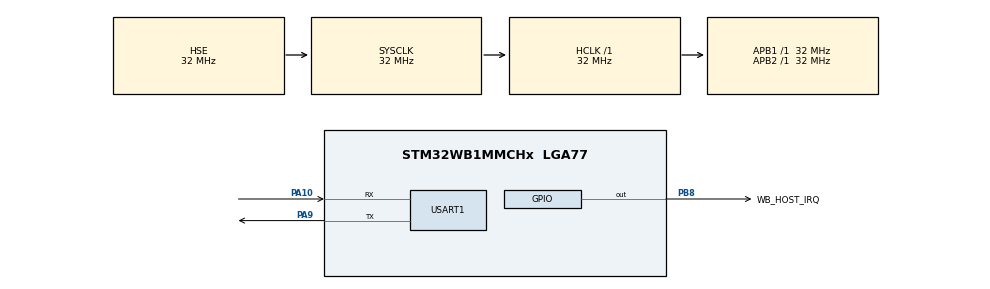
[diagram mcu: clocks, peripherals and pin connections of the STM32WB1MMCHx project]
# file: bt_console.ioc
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CRC.CRCLength=CRC_POLYLENGTH_16B
CRC.DefaultInitValueUse=DEFAULT_INIT_VALUE_DISABLE
CRC.DefaultPolynomialUse=DEFAULT_POLYNOMIAL_DISABLE
CRC.GeneratingPolynomial=X12+X5+X0
CRC.InitValue=0xFFFF
IWDG.Prescaler=IWDG_PRESCALER_128
IWDG.Reload=1999
Mcu.Family=STM32WB
Mcu.Name=STM32WB1MMCHx
Mcu.Package=LGA77
NVIC.HSEM_IRQn=true\:0\:0\:false\:false\:true\:false\:true\:true
NVIC.IPCC_C1_RX_IRQn=true\:0\:0\:false\:false\:true\:true\:true\:true
NVIC.IPCC_C1_TX_IRQn=true\:0\:0\:false\:false\:true\:true\:true\:true
NVIC.LPTIM1_IRQn=true\:6\:0\:true\:false\:true\:true\:true\:true
NVIC.PriorityGroup=NVIC_PRIORITYGROUP_4
NVIC.RTC_WKUP_IRQn=true\:3\:0\:true\:false\:true\:true\:true\:true
NVIC.USART1_IRQn=true\:5\:0\:true\:false\:true\:true\:true\:true
PA10.Mode=Asynchronous
PA10.Signal=USART1_RX
PA13.Mode=Serial_Wire
PA13.Signal=SYS_JTMS-SWDIO
PA14.Mode=Serial_Wire
PA14.Signal=SYS_JTCK-SWCLK
PA9.Mode=Asynchronous
PA9.Signal=USART1_TX
PB8.GPIO_Label=WB_HOST_IRQ
PB8.Signal=GPIO_Output
ProjectManager.HeapSize=0x200
ProjectManager.StackSize=0x400
ProjectManager.TargetToolchain=STM32CubeIDE
RCC.AHBFreq_Value=32000000
RCC.APB1Freq_Value=32000000
RCC.APB1TimFreq_Value=32000000
RCC.APB2Freq_Value=32000000
RCC.APB2TimFreq_Value=32000000
RCC.APB3Freq_Value=16000000
RCC.CortexFreq_Value=32000000
RCC.HCLKFreq_Value=32000000
RCC.HSE_VALUE=32000000
RCC.HSI_VALUE=16000000
RCC.LPTIM1CLockSelection=RCC_LPTIM1CLKSOURCE_LSE
RCC.RFWKPClockSelection=RCC_RFWKPCLKSOURCE_LSE
RCC.RTCClockSelection=RCC_RTCCLKSOURCE_LSE
RCC.SMPSCLockSelectionVirtual=RCC_SMPSCLKSOURCE_HSE
RCC.SMPSDivider=4
RCC.SYSCLKFreq_VALUE=32000000
RCC.SYSCLKSource=RCC_SYSCLKSOURCE_HSE
RCC.VCOOutputFreq_Value=32000000
STM32_WPAN.BLE_APPLICATION_TYPE=BLE_CLIENT_PROFILE
STM32_WPAN.BLE_CFG_CLT_MAX_NBR_CB=2
STM32_WPAN.CFG_LSCLK_LSE=0
USART1.VirtualMode-Asynchronous=VM_ASYNC
VP_CRC_VS_CRC.Mode=CRC_Activate
VP_HSEM_VS_HSEM.Mode=HSEM_Activate
VP_IPCC_VS_IPCC.Mode=IPCC_Activate
VP_IWDG_VS_IWDG.Mode=IWDG_Activate
VP_LPTIM1_VS_LPTIM_counterModeInternalClock.Mode=Counts__internal_clock_event_00
VP_MEMORYMAP_VS_MEMORYMAP.Mode=CurAppReg
VP_RCC_V_OSC32_IN.Mode=LSE-External-Clock-Source
VP_RCC_V_OSC_IN.Mode=HSE-External-Clock-Source
VP_RF_VS_RF.Mode=RF_Activate
VP_RTC_VS_RTC_Activate.Mode=RTC_Enabled
VP_RTC_VS_RTC_WakeUp_intern.Mode=WakeUp
VP_SEQUENCER_VS_SEQUENCER.Mode=SEQUENCER_Enabled
VP_STM32_WPAN_VS_BLE_HOST.Mode=STM32_WPAN_Enabled
VP_TINY_LPM_VS_TINY_LPM.Mode=TINY_LPM_Enabled
board=custom

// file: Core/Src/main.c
/* USER CODE BEGIN Header */
/**
  ******************************************************************************
  * @file           : main.c
  * @brief          : Main program body
  ******************************************************************************
  * @attention
  *
  * Copyright (c) 2026 STMicroelectronics.
  * All rights reserved.
  *
  * This software is licensed under terms that can be found in the LICENSE file
  * in the root directory of this software component.
  * If no LICENSE file comes with this software, it is provided AS-IS.
  *
  ******************************************************************************
  */
/* USER CODE END Header */
#include "main.h"

/* USER CODE BEGIN Includes */

#include "error.h"
#include "watchdog.h"

/* USER CODE END Includes */

CRC_HandleTypeDef hcrc;

IPCC_HandleTypeDef hipcc;

IWDG_HandleTypeDef hiwdg;

LPTIM_HandleTypeDef hlptim1;

RTC_HandleTypeDef hrtc;

UART_HandleTypeDef huart1;

void SystemClock_Config(void);
void PeriphCommonClock_Config(void);
static void MX_GPIO_Init(void);
static void MX_IPCC_Init(void);
static void MX_RTC_Init(void);
static void MX_USART1_UART_Init(void);
static void MX_CRC_Init(void);
static void MX_LPTIM1_Init(void);
static void MX_IWDG_Init(void);
static void MX_RF_Init(void);

int main(void)
{

  /* MCU Configuration--------------------------------------------------------*/

  /* Reset of all peripherals, Initializes the Flash interface and the Systick. */
  HAL_Init();
  /* Config code for STM32_WPAN (HSE Tuning must be done before system clock configuration) */
  MX_APPE_Config();

  /* Configure the system clock */
  SystemClock_Config();

  /* Configure the peripherals common clocks */
  PeriphCommonClock_Config();

  /* IPCC initialisation */
  MX_IPCC_Init();

  /* Initialize all configured peripherals */
  MX_GPIO_Init();
  MX_RTC_Init();
  MX_USART1_UART_Init();
  MX_CRC_Init();
  MX_LPTIM1_Init();
  MX_IWDG_Init();
  MX_RF_Init();

  /* Init code for STM32_WPAN */
  MX_APPE_Init();

  /* Infinite loop */
  while (1)
  {
    MX_APPE_Process();

    /* USER CODE BEGIN 3 */
    watchdog_process();
  }
  /* USER CODE END 3 */
}

void SystemClock_Config(void)
{
  RCC_OscInitTypeDef RCC_OscInitStruct = {0};
  RCC_ClkInitTypeDef RCC_ClkInitStruct = {0};

  /** Configure LSE Drive Capability
  */
  HAL_PWR_EnableBkUpAccess();
  __HAL_RCC_LSEDRIVE_CONFIG(RCC_LSEDRIVE_MEDIUMHIGH);

  /** Initializes the RCC Oscillators according to the specified parameters
  * in the RCC_OscInitTypeDef structure.
  */
  RCC_OscInitStruct.OscillatorType = RCC_OSCILLATORTYPE_HSI|RCC_OSCILLATORTYPE_LSI1
                              |RCC_OSCILLATORTYPE_HSE|RCC_OSCILLATORTYPE_LSE;
  RCC_OscInitStruct.HSEState = RCC_HSE_ON;
  RCC_OscInitStruct.LSEState = RCC_LSE_ON;
  RCC_OscInitStruct.HSIState = RCC_HSI_ON;
  RCC_OscInitStruct.HSICalibrationValue = RCC_HSICALIBRATION_DEFAULT;
  RCC_OscInitStruct.LSIState = RCC_LSI_ON;
  RCC_OscInitStruct.PLL.PLLState = RCC_PLL_NONE;
  if (HAL_RCC_OscConfig(&RCC_OscInitStruct) != HAL_OK)
  {
    Error_Handler();
  }

  /** Configure the SYSCLKSource, HCLK, PCLK1 and PCLK2 clocks dividers
  */
  RCC_ClkInitStruct.ClockType = RCC_CLOCKTYPE_HCLK4|RCC_CLOCKTYPE_HCLK2
                              |RCC_CLOCKTYPE_HCLK|RCC_CLOCKTYPE_SYSCLK
                              |RCC_CLOCKTYPE_PCLK1|RCC_CLOCKTYPE_PCLK2;
  RCC_ClkInitStruct.SYSCLKSource = RCC_SYSCLKSOURCE_HSE;
  RCC_ClkInitStruct.AHBCLKDivider = RCC_SYSCLK_DIV1;
  RCC_ClkInitStruct.APB1CLKDivider = RCC_HCLK_DIV1;
  RCC_ClkInitStruct.APB2CLKDivider = RCC_HCLK_DIV1;
  RCC_ClkInitStruct.AHBCLK2Divider = RCC_SYSCLK_DIV1;
  RCC_ClkInitStruct.AHBCLK4Divider = RCC_SYSCLK_DIV1;

  if (HAL_RCC_ClockConfig(&RCC_ClkInitStruct, FLASH_LATENCY_1) != HAL_OK)
  {
    Error_Handler();
  }
}

void PeriphCommonClock_Config(void)
{
  RCC_PeriphCLKInitTypeDef PeriphClkInitStruct = {0};

  /** Initializes the peripherals clock
  */
  PeriphClkInitStruct.PeriphClockSelection = RCC_PERIPHCLK_SMPS|RCC_PERIPHCLK_RFWAKEUP;
  PeriphClkInitStruct.RFWakeUpClockSelection = RCC_RFWKPCLKSOURCE_LSE;
  PeriphClkInitStruct.SmpsClockSelection = RCC_SMPSCLKSOURCE_HSE;
  PeriphClkInitStruct.SmpsDivSelection = RCC_SMPSCLKDIV_RANGE1;

  if (HAL_RCCEx_PeriphCLKConfig(&PeriphClkInitStruct) != HAL_OK)
  {
    Error_Handler();
  }
}

static void MX_CRC_Init(void)
{

  hcrc.Instance = CRC;
  hcrc.Init.DefaultPolynomialUse = DEFAULT_POLYNOMIAL_DISABLE;
  hcrc.Init.DefaultInitValueUse = DEFAULT_INIT_VALUE_DISABLE;
  hcrc.Init.GeneratingPolynomial = 4129;
  hcrc.Init.CRCLength = CRC_POLYLENGTH_16B;
  hcrc.Init.InitValue = 0xFFFF;
  hcrc.Init.InputDataInversionMode = CRC_INPUTDATA_INVERSION_NONE;
  hcrc.Init.OutputDataInversionMode = CRC_OUTPUTDATA_INVERSION_DISABLE;
  hcrc.InputDataFormat = CRC_INPUTDATA_FORMAT_BYTES;
  if (HAL_CRC_Init(&hcrc) != HAL_OK)
  {
    Error_Handler();
  }

}

static void MX_IPCC_Init(void)
{

  hipcc.Instance = IPCC;
  if (HAL_IPCC_Init(&hipcc) != HAL_OK)
  {
    Error_Handler();
  }

}

static void MX_IWDG_Init(void)
{

  hiwdg.Instance = IWDG;
  hiwdg.Init.Prescaler = IWDG_PRESCALER_128;
  hiwdg.Init.Window = 4095;
  hiwdg.Init.Reload = 1999;
  if (HAL_IWDG_Init(&hiwdg) != HAL_OK)
  {
    Error_Handler();
  }

}

static void MX_LPTIM1_Init(void)
{

  hlptim1.Instance = LPTIM1;
  hlptim1.Init.Clock.Source = LPTIM_CLOCKSOURCE_APBCLOCK_LPOSC;
  hlptim1.Init.Clock.Prescaler = LPTIM_PRESCALER_DIV1;
  hlptim1.Init.Trigger.Source = LPTIM_TRIGSOURCE_SOFTWARE;
  hlptim1.Init.OutputPolarity = LPTIM_OUTPUTPOLARITY_HIGH;
  hlptim1.Init.UpdateMode = LPTIM_UPDATE_IMMEDIATE;
  hlptim1.Init.CounterSource = LPTIM_COUNTERSOURCE_INTERNAL;
  hlptim1.Init.Input1Source = LPTIM_INPUT1SOURCE_GPIO;
  hlptim1.Init.Input2Source = LPTIM_INPUT2SOURCE_GPIO;
  if (HAL_LPTIM_Init(&hlptim1) != HAL_OK)
  {
    Error_Handler();
  }

}

static void MX_RF_Init(void)
{

}

static void MX_RTC_Init(void)
{

  /** Initialize RTC Only
  */
  hrtc.Instance = RTC;
  hrtc.Init.HourFormat = RTC_HOURFORMAT_24;
  hrtc.Init.AsynchPrediv = CFG_RTC_ASYNCH_PRESCALER;
  hrtc.Init.SynchPrediv = CFG_RTC_SYNCH_PRESCALER;
  hrtc.Init.OutPut = RTC_OUTPUT_DISABLE;
  hrtc.Init.OutPutPolarity = RTC_OUTPUT_POLARITY_HIGH;
  hrtc.Init.OutPutRemap = RTC_OUTPUT_REMAP_NONE;
  if (HAL_RTC_Init(&hrtc) != HAL_OK)
  {
    Error_Handler();
  }

  /** Enable the WakeUp
  */
  if (HAL_RTCEx_SetWakeUpTimer_IT(&hrtc, 0, RTC_WAKEUPCLOCK_RTCCLK_DIV16) != HAL_OK)
  {
    Error_Handler();
  }

}

static void MX_USART1_UART_Init(void)
{

  huart1.Instance = USART1;
  huart1.Init.BaudRate = 115200;
  huart1.Init.WordLength = UART_WORDLENGTH_8B;
  huart1.Init.StopBits = UART_STOPBITS_1;
  huart1.Init.Parity = UART_PARITY_NONE;
  huart1.Init.Mode = UART_MODE_TX_RX;
  huart1.Init.HwFlowCtl = UART_HWCONTROL_NONE;
  huart1.Init.OverSampling = UART_OVERSAMPLING_16;
  huart1.Init.OneBitSampling = UART_ONE_BIT_SAMPLE_DISABLE;
  huart1.Init.ClockPrescaler = UART_PRESCALER_DIV1;
  huart1.AdvancedInit.AdvFeatureInit = UART_ADVFEATURE_NO_INIT;
  if (HAL_UART_Init(&huart1) != HAL_OK)
  {
    Error_Handler();
  }
  if (HAL_UARTEx_SetTxFifoThreshold(&huart1, UART_TXFIFO_THRESHOLD_1_8) != HAL_OK)
  {
    Error_Handler();
  }
  if (HAL_UARTEx_SetRxFifoThreshold(&huart1, UART_RXFIFO_THRESHOLD_1_8) != HAL_OK)
  {
    Error_Handler();
  }
  if (HAL_UARTEx_DisableFifoMode(&huart1) != HAL_OK)
  {
    Error_Handler();
  }

}

static void MX_GPIO_Init(void)
{
  GPIO_InitTypeDef GPIO_InitStruct = {0};

  /* GPIO Ports Clock Enable */
  __HAL_RCC_GPIOB_CLK_ENABLE();
  __HAL_RCC_GPIOA_CLK_ENABLE();

  /*Configure GPIO pin Output Level */
  HAL_GPIO_WritePin(WB_HOST_IRQ_GPIO_Port, WB_HOST_IRQ_Pin, GPIO_PIN_RESET);

  /*Configure GPIO pin : WB_HOST_IRQ_Pin */
  GPIO_InitStruct.Pin = WB_HOST_IRQ_Pin;
  GPIO_InitStruct.Mode = GPIO_MODE_OUTPUT_PP;
  GPIO_InitStruct.Pull = GPIO_NOPULL;
  GPIO_InitStruct.Speed = GPIO_SPEED_FREQ_LOW;
  HAL_GPIO_Init(WB_HOST_IRQ_GPIO_Port, &GPIO_InitStruct);

}

void Error_Handler(void)
{
  /* USER CODE BEGIN Error_Handler_Debug */
  /* User can add his own implementation to report the HAL error return state */

  error_fatal();

  /* USER CODE END Error_Handler_Debug */
}
